# LCD_F_356.0 register map
Vendor: Texas Instruments
Peripheral module from a debugger description file (folder MSP432).
Registers are 8-bit, access not given, no defined reset value unless marked. A register's access mark holds for its fields unless they carry their own. Offsets are as the file gives them; lines under a group give offsets from that group; [hi:lo] are bit positions; {n}, {i} and the like mark numbered series; 'fields as' and 'values as' point back to an identical list; <NAME> marks a mode.

## LCD_F
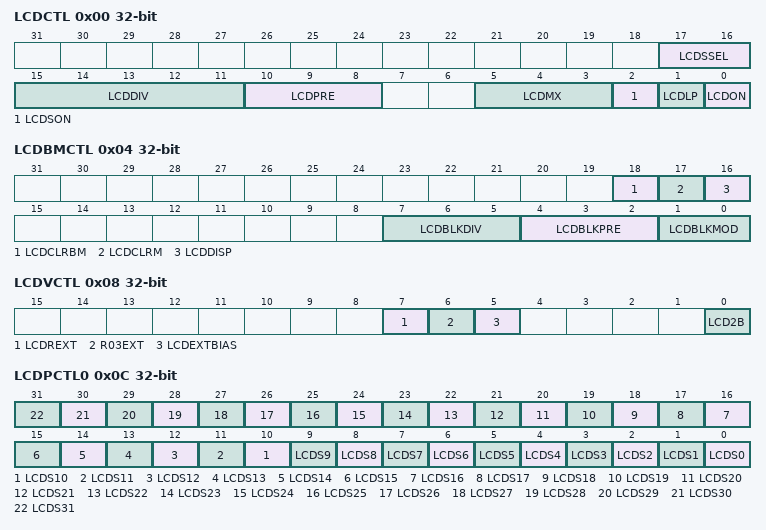
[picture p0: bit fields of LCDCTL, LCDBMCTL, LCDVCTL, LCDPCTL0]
0x00 LCDCTL 32-bit rw — LCD_F control
  [17:16] LCDSSEL — Clock source select
    0=ACLK; 1=VLOCLK; 2=REFOCLK; 3=LFXTCLK
  [15:11] LCDDIV — LCD frequency divider
    {v}=Divide by {v+1} (v=0..31)
  [10:8] LCDPRE — LCD frequency pre-scaler
    0=Divide by 1; 1=Divide by 2; 2=Divide by 4; 3=Divide by 8; 4=Divide by 16; 5=Divide by 32
  [5:3] LCDMX — LCD mux rate
    0=Static; {v}={v+1}-mux (v=1..7)
  [2] LCDSON — LCD segments on
    0=All LCD segments are off; 1=All LCD segments are enabled and on or off according to their corresponding memory location
  [1] LCDLP — LCD Low-power Waveform
    0=Standard LCD waveforms on segment and common lines selected; 1=Low-power LCD waveforms on segment and common lines selected
  [0] LCDON
    0=LCD module off; 1=LCD module on
0x04 LCDBMCTL 32-bit rw — LCD_F blinking and memory control
  [18] LCDCLRBM — Clear LCD blinking memory
    0=Contents of blinking memory registers LCDBMx remain unchanged; 1=Clear content of all blinking memory registers LCDBMx
  [17] LCDCLRM — Clear LCD memory
    0=Contents of LCD memory registers LCDMx remain unchanged; 1=Clear content of all LCD memory registers LCDMx
  [16] LCDDISP — Select LCD memory registers for display
    0=Display content of LCD memory registers LCDMx; 1=Display content of LCD blinking memory registers LCDBMx
  [7:5] LCDBLKDIV — Clock divider for blinking frequency
    {v}=Divide by {v+1} (v=0..7)
  [4:2] LCDBLKPRE — Clock pre-scaler for blinking frequency
    0=Divide by 512; 1=Divide by 1024; 2=Divide by 2048; 3=Divide by 4096; 4=Divide by 8162; 5=Divide by 16384; 6=Divide by 32768; 7=Divide by 65536
  [1:0] LCDBLKMOD — Blinking mode
    0=Blinking disabled; 1=Blinking of individual segments as enabled in blinking memory register LCDBMx; 2=Blinking of all segments; 3=Switching between display contents as stored in LCDMx and LCDBMx memory registers
0x08 LCDVCTL 32-bit rw — LCD_F voltage control
  [7] LCDREXT — V2 to V4 voltage on external Rx3 pins
    0=Internally generated V2 to V4 are not switched to pins (LCDEXTBIAS = 0); 1=Internally generated V2 to V4 are switched to pins (LCDEXTBIAS = 0)
  [6] R03EXT — V5 voltage select
    0=V5 is VSS; 1=V5 is sourced from the R03 pin
  [5] LCDEXTBIAS — V2 to V4 voltage select
    0=V2 to V4 are generated internally; 1=V2 to V4 are sourced externally and the internal bias generator is switched off
  [0] LCD2B — Bias select.
    0=1/3 bias; 1=For 5-mux to 8-mux modes:1/2 bias. For 5-mux to 8-mux modes - 1/4 bias.
0x0C LCDPCTL0 32-bit rw — LCD_F port control 0
  [all] fields
    0=Multiplexed pins are port functions; 1=Pins are LCD functions
  [n] LCDS{n} (n=0..31) — LCD pin {n} enable
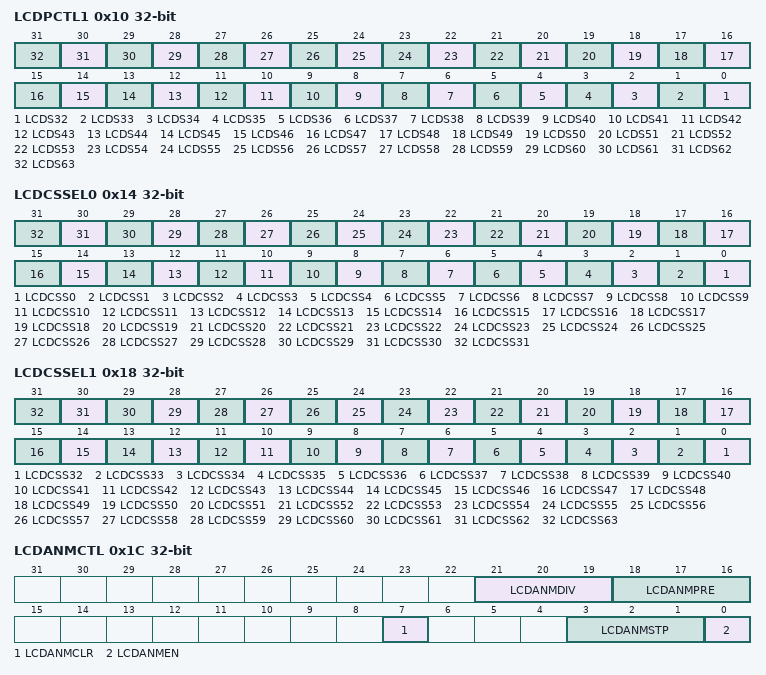
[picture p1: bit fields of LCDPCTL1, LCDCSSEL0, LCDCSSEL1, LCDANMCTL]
0x10 LCDPCTL1 32-bit rw — LCD_F port control 1
  [all] fields
    values as the fields of LCDPCTL0
  [n-32] LCDS{n} (n=32..63) — LCD pin {n} enable
0x14 LCDCSSEL0 32-bit rw — LCD_F COM/SEG select register 0
  [all] fields
    0=Segment line; 1=Common line
  [n] LCDCSS{n} (n=0..31) — L{n} Com Seg select
0x18 LCDCSSEL1 32-bit rw — LCD_F COM/SEG select register 1
  [all] fields
    0=Segment line; 1=Common line
  [n-32] LCDCSS{n} (n=32..63) — L{n} Com Seg select
0x1C LCDANMCTL 32-bit rw — LCD_F Animation Control Register
  [21:19] LCDANMDIV — Clock divider for animation frequency
    {v}=Divide by {v+1} (v=0..7)
  [18:16] LCDANMPRE — Clock pre-scaler for animation frequency
    values as LCDBMCTL.LCDBLKPRE
  [7] LCDANMCLR — Clear Animation Memory
    0=Contents of animation memory registers LCDANMx remain unchanged; 1=Clear content of all animation memory registers LCDANMx
  [3:1] LCDANMSTP — Number of Amimation frames
    0=T0; {v}=T0 to T{v} (v=1..7)
  [0] LCDANMEN — Enable Animation
    0=Animation disabled; 1=Animation enabled
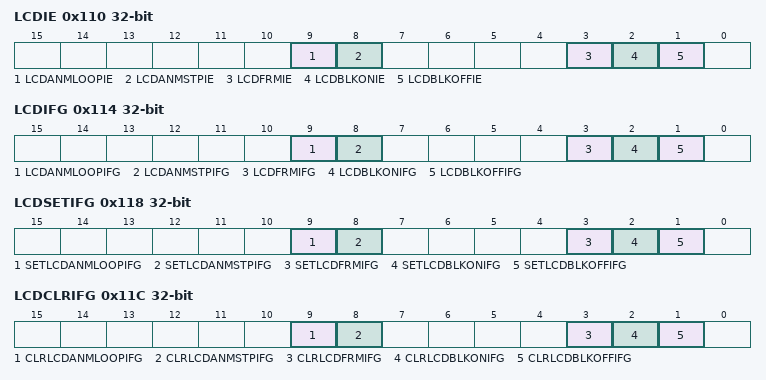
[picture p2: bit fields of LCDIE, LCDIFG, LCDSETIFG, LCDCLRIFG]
0x110 LCDIE 32-bit rw — LCD_F interrupt enable register
  [all] fields
    0=Interrupt disabled; 1=Interrupt enabled
  [9] LCDANMLOOPIE — LCD Animation loop interrupt enable
  [8] LCDANMSTPIE — LCD Animation step interrupt enable
  [3] LCDFRMIE — LCD Frame interrupt enable
  [2] LCDBLKONIE — LCD Blink, segments on interrupt enable
  [1] LCDBLKOFFIE — LCD Blink, segments off interrupt enable
0x114 LCDIFG 32-bit ro — LCD_F interrupt flag register
  [9] LCDANMLOOPIFG — LCD Animation loop interrupt flag
    0=No interrupt pending; 1=Interrupt due to LCD Animation loop on
  [8] LCDANMSTPIFG — LCD Animation step interrupt flag
    0=No interrupt pending; 1=Interrupt due to LCD Animation step on
  [3] LCDFRMIFG — LCD Frame interrupt flag
    0=No interrupt pending; 1=Interrupt due to LCD frame
  [2] LCDBLKONIFG — LCD Blink, segments on interrupt flag
    0=No interrupt pending; 1=Interrupt due to LCD Blink, segments on
  [1] LCDBLKOFFIFG — LCD Blink, segments off interrupt flag
    values as LCDBLKONIFG
0x118 LCDSETIFG 32-bit rw — LCD_F set interrupt flag register
  [all] fields
    0=No effect; 1=Sets interrupt flag
  [9] SETLCDANMLOOPIFG — Sets LCDANMLOOPIFG
  [8] SETLCDANMSTPIFG — Sets LCDANMSTPIFG
  [3] SETLCDFRMIFG — Sets LCDFRMIFG
  [2] SETLCDBLKONIFG — Sets LCDBLKONIFG
  [1] SETLCDBLKOFFIFG — Sets LCDBLKOFFIFG
0x11C LCDCLRIFG 32-bit rw — LCD_F clear interrupt flag register
  [all] fields
    0=No effect; 1=Clears pending interrupt flag
  [9] CLRLCDANMLOOPIFG — Clears LCDANMLOOPIFG
  [8] CLRLCDANMSTPIFG — Clears LCDANMSTPIFG
  [3] CLRLCDFRMIFG — Clears LCDFRMIFG
  [2] CLRLCDBLKONIFG — Clears LCDBLKONIFG
  [1] CLRLCDBLKOFFIFG — Clears LCDBLKOFFIFG
0x120 LCDM — LCD memory registers
0x121 LCDM — LCD memory registers
0x122 LCDM — LCD memory registers
0x123 LCDM — LCD memory registers
0x124 LCDM — LCD memory registers
0x125 LCDM — LCD memory registers
0x126 LCDM — LCD memory registers
0x127 LCDM — LCD memory registers
0x128 LCDM — LCD memory registers
0x129 LCDM — LCD memory registers
0x12A LCDM — LCD memory registers
0x12B LCDM — LCD memory registers
0x12C LCDM — LCD memory registers
0x12D LCDM — LCD memory registers
0x12E LCDM — LCD memory registers
0x12F LCDM — LCD memory registers
0x130 LCDM — LCD memory registers
0x131 LCDM — LCD memory registers
0x132 LCDM — LCD memory registers
0x133 LCDM — LCD memory registers
0x134 LCDM — LCD memory registers
0x135 LCDM — LCD memory registers
0x136 LCDM — LCD memory registers
0x137 LCDM — LCD memory registers
0x138 LCDM — LCD memory registers
0x139 LCDM — LCD memory registers
0x13A LCDM — LCD memory registers
0x13B LCDM — LCD memory registers
0x13C LCDM — LCD memory registers
0x13D LCDM — LCD memory registers
0x13E LCDM — LCD memory registers
0x13F LCDM — LCD memory registers
0x140 LCDM — LCD memory registers
0x141 LCDM — LCD memory registers
0x142 LCDM — LCD memory registers
0x143 LCDM — LCD memory registers
0x144 LCDM — LCD memory registers
0x145 LCDM — LCD memory registers
0x146 LCDM — LCD memory registers
0x147 LCDM — LCD memory registers
0x148 LCDM — LCD memory registers
0x149 LCDM — LCD memory registers
0x14A LCDM — LCD memory registers
0x14B LCDM — LCD memory registers
0x14C LCDM — LCD memory registers
0x14D LCDM — LCD memory registers
0x14E LCDM — LCD memory registers
0x14F LCDM — LCD memory registers
0x160 LCDBM — LCD Blinking memory registers
0x161 LCDBM — LCD Blinking memory registers
0x162 LCDBM — LCD Blinking memory registers
0x163 LCDBM — LCD Blinking memory registers
0x164 LCDBM — LCD Blinking memory registers
0x165 LCDBM — LCD Blinking memory registers
0x166 LCDBM — LCD Blinking memory registers
0x167 LCDBM — LCD Blinking memory registers
0x168 LCDBM — LCD Blinking memory registers
0x169 LCDBM — LCD Blinking memory registers
0x16A LCDBM — LCD Blinking memory registers
0x16B LCDBM — LCD Blinking memory registers
0x16C LCDBM — LCD Blinking memory registers
0x16D LCDBM — LCD Blinking memory registers
0x16E LCDBM — LCD Blinking memory registers
0x16F LCDBM — LCD Blinking memory registers
0x170 LCDBM — LCD Blinking memory registers
0x171 LCDBM — LCD Blinking memory registers
0x172 LCDBM — LCD Blinking memory registers
0x173 LCDBM — LCD Blinking memory registers
0x174 LCDBM — LCD Blinking memory registers
0x175 LCDBM — LCD Blinking memory registers
0x176 LCDBM — LCD Blinking memory registers
0x177 LCDBM — LCD Blinking memory registers
0x178 LCDBM — LCD Blinking memory registers
0x179 LCDBM — LCD Blinking memory registers
0x17A LCDBM — LCD Blinking memory registers
0x17B LCDBM — LCD Blinking memory registers
0x17C LCDBM — LCD Blinking memory registers
0x17D LCDBM — LCD Blinking memory registers
0x17E LCDBM — LCD Blinking memory registers
0x17F LCDBM — LCD Blinking memory registers
0x180 LCDBM — LCD Blinking memory registers
0x181 LCDBM — LCD Blinking memory registers
0x182 LCDBM — LCD Blinking memory registers
0x183 LCDBM — LCD Blinking memory registers
0x184 LCDBM — LCD Blinking memory registers
0x185 LCDBM — LCD Blinking memory registers
0x186 LCDBM — LCD Blinking memory registers
0x187 LCDBM — LCD Blinking memory registers
0x188 LCDBM — LCD Blinking memory registers
0x189 LCDBM — LCD Blinking memory registers
0x18A LCDBM — LCD Blinking memory registers
0x18B LCDBM — LCD Blinking memory registers
0x18C LCDBM — LCD Blinking memory registers
0x18D LCDBM — LCD Blinking memory registers
0x18E LCDBM — LCD Blinking memory registers
0x18F LCDBM — LCD Blinking memory registers
0x1A0 LCDANM — LCD Animation memory registers
0x1A1 LCDANM — LCD Animation memory registers
0x1A2 LCDANM — LCD Animation memory registers
0x1A3 LCDANM — LCD Animation memory registers
0x1A4 LCDANM — LCD Animation memory registers
0x1A5 LCDANM — LCD Animation memory registers
0x1A6 LCDANM — LCD Animation memory registers
0x1A7 LCDANM — LCD Animation memory registers
